VERSION "0.1"

NS_ :

BS_:

BU_: User ADB_PC_DC01

BO_ 8519744 DC01_Mode_Set: 2 User
 SG_ connection : 8|8@1+ (1,0) [0|0] ""  ADB_PC_DC01
 SG_ mode : 0|8@1+ (1,0) [0|0] ""  ADB_PC_DC01

BO_ 8519745 DC01_Mode_Applied: 2 ADB_PC_DC01
 SG_ connection : 8|8@1+ (1,0) [0|0] ""  User
 SG_ mode : 0|8@1+ (1,0) [0|0] ""  User

BO_ 8519746 DC01_faults: 8 ADB_PC_DC01

BO_ 8519747 DC01_warning: 8 ADB_PC_DC01

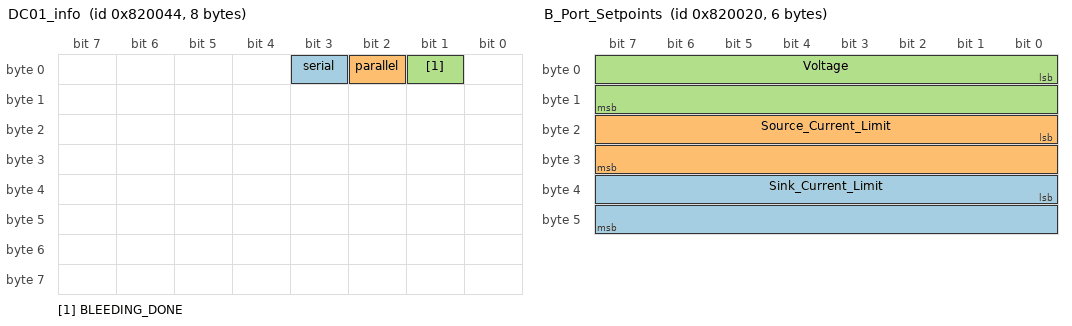
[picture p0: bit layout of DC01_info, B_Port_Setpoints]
BO_ 8519748 DC01_info: 8 ADB_PC_DC01
 SG_ serial : 3|1@1+ (1,0) [0|0] ""  User
 SG_ parallel : 2|1@1+ (1,0) [0|0] ""  User
 SG_ BLEEDING_DONE : 1|1@1+ (1,0) [0|0] ""  User

BO_ 8519712 B_Port_Setpoints: 6 User
 SG_ Sink_Current_Limit : 32|16@1+ (0.1,0) [0|220] "A"  ADB_PC_DC01
 SG_ Source_Current_Limit : 16|16@1+ (0.1,0) [0|220] "A"  ADB_PC_DC01
 SG_ Voltage : 0|16@1+ (0.1,0) [0|1500] "V"  ADB_PC_DC01

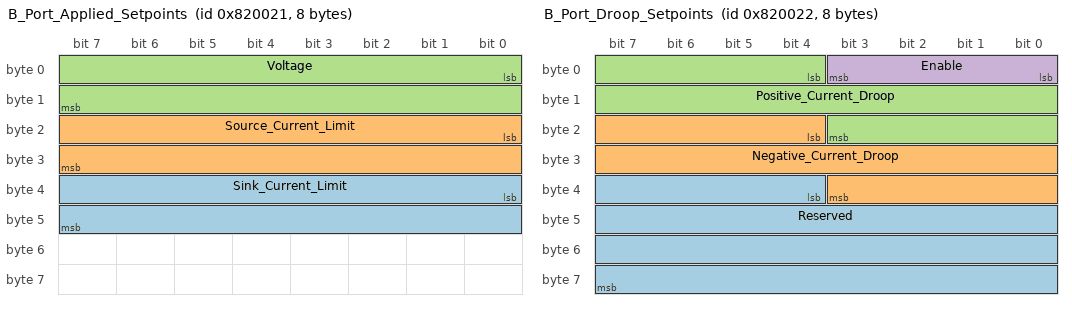
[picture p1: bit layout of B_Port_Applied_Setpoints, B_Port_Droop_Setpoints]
BO_ 8519713 B_Port_Applied_Setpoints: 8 ADB_PC_DC01
 SG_ Sink_Current_Limit : 32|16@1+ (0.1,0) [0|0] "A"  User
 SG_ Source_Current_Limit : 16|16@1+ (0.1,0) [0|0] "A"  User
 SG_ Voltage : 0|16@1+ (0.1,0) [0|0] "V"  User

BO_ 8519714 B_Port_Droop_Setpoints: 8 User
 SG_ Reserved : 36|28@1+ (1,0) [0|0] ""  ADB_PC_DC01
 SG_ Negative_Current_Droop : 20|16@1+ (0.01,0) [0|0] "Ohm"  ADB_PC_DC01
 SG_ Positive_Current_Droop : 4|16@1+ (0.01,0) [0|0] "Ohm"  ADB_PC_DC01
 SG_ Enable : 0|4@1+ (1,0) [0|0] ""  ADB_PC_DC01

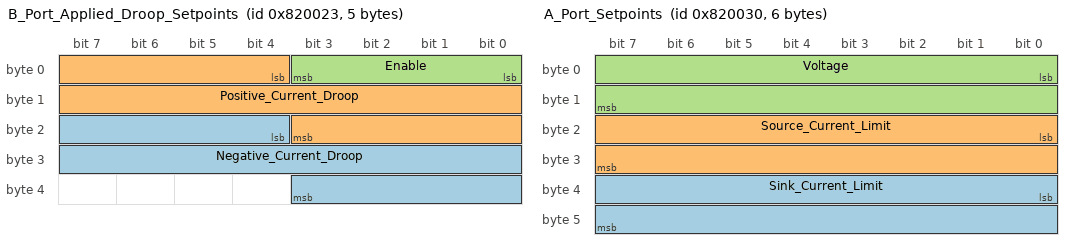
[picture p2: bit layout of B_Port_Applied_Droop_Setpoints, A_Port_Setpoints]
BO_ 8519715 B_Port_Applied_Droop_Setpoints: 5 ADB_PC_DC01
 SG_ Negative_Current_Droop : 20|16@1+ (0.01,0) [0|0] "Ohm"  User
 SG_ Positive_Current_Droop : 4|16@1+ (0.01,0) [0|0] "Ohm"  User
 SG_ Enable : 0|4@1+ (1,0) [0|0] ""  User

BO_ 8519716 B_Port_Measurements: 4 ADB_PC_DC01
 SG_ Current : 16|16@1- (0.1,0) [0|0] "A"  User
 SG_ Voltage : 0|16@1+ (0.1,0) [0|0] "V"  User

BO_ 8519730 A_Port_Measurements: 4 ADB_PC_DC01
 SG_ Current : 16|16@1- (0.1,0) [0|0] "A"  User
 SG_ Voltage : 0|16@1+ (0.1,0) [0|0] "V"  User

BO_ 8519728 A_Port_Setpoints: 6 User
 SG_ Sink_Current_Limit : 32|16@1+ (0.1,0) [0|220] "A"  ADB_PC_DC01
 SG_ Source_Current_Limit : 16|16@1+ (0.1,0) [0|220] "A"  ADB_PC_DC01
 SG_ Voltage : 0|16@1+ (0.1,0) [0|1500] "V"  ADB_PC_DC01

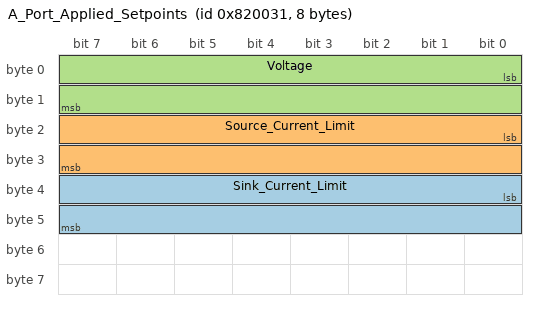
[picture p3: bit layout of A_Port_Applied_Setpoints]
BO_ 8519729 A_Port_Applied_Setpoints: 8 ADB_PC_DC01
 SG_ Sink_Current_Limit : 32|16@1+ (0.1,0) [0|0] "A"  User
 SG_ Source_Current_Limit : 16|16@1+ (0.1,0) [0|0] "A"  User
 SG_ Voltage : 0|16@1+ (0.1,0) [0|0] "V"  User

CM_ BO_ 8519744 "Set the mode of AC01";
CM_ SG_ 8519744 connection "require connection";
CM_ SG_ 8519744 mode "require mode";
CM_ BO_ 8519745 "read back the modes";
CM_ SG_ 8519745 connection "connection mode";
CM_ SG_ 8519745 mode "actual mode";
CM_ BO_ 8519746 "DC01 Critical and Error Faults";
CM_ BO_ 8519747 "DC01 Warning";
CM_ BO_ 8519748 "DC01 Info";
CM_ SG_ 8519748 serial "Afe are in series ";
CM_ SG_ 8519748 parallel "Afe are in parallel";
CM_ SG_ 8519748 BLEEDING_DONE "Current limited by power max ";
CM_ BO_ 8519712 "The setpoints control the behaviour of the B Port of the DC01";
CM_ SG_ 8519712 Sink_Current_Limit "The maximum current that the AC01 will sink into the B port";
CM_ SG_ 8519712 Source_Current_Limit "The maximum current that the DC01 will source on the B port";
CM_ SG_ 8519712 Voltage "Control the target B port voltage. This voltage will be maintained as long as the current required to do so is smaller than the current limits specified in this message";
CM_ BO_ 8519713 "The setpoints that are currently used by the DC01. This message allows to validate that the setpoints have been properly applied.";
CM_ SG_ 8519713 Sink_Current_Limit "The maximum amount of current that the DC01 will sink into the B port";
CM_ SG_ 8519713 Source_Current_Limit "The maximum current that the DC01 will source on the B Port";
CM_ SG_ 8519713 Voltage "The voltage target of the B port";
CM_ BO_ 8519714 "Setpoints for applying Droop on the B Port. Droop is needed for paralleling multiple DC01";
CM_ SG_ 8519714 Reserved "This space is reserved. This region should contain only '0's";
CM_ SG_ 8519714 Negative_Current_Droop "The droop resistance to apply for current flowing in to the B Port (DC current is negative)";
CM_ SG_ 8519714 Positive_Current_Droop "The droop resistance to apply for current flowing out of the B port (DC current is positive)";
CM_ SG_ 8519714 Enable "Enable DC Droop. If this feature is enabled the output voltage of the B port varies with output current.";
CM_ BO_ 8519715 "Droop setpoints that are applied by the DC01";
CM_ SG_ 8519715 Negative_Current_Droop "The droop resistance applied for current flowing in to the B Port (DC current is negative)";
CM_ SG_ 8519715 Positive_Current_Droop "The droop resistance applied for current flowing out of the B port (DC current is positive)";
CM_ SG_ 8519715 Enable "Show is DC Droop is enabled.";
CM_ BO_ 8519716 "Measurements of the B port";
CM_ SG_ 8519716 Current "Current through the B Port";
CM_ SG_ 8519716 Voltage "Voltage on the B Port";
CM_ BO_ 8519730 "Measurements of the A port";
CM_ SG_ 8519730 Current "Current through the A Port";
CM_ SG_ 8519730 Voltage "Voltage on the A Port";
CM_ BO_ 8519728 "The setpoints control the behaviour of the A Port of the DC01";
CM_ SG_ 8519728 Sink_Current_Limit "The maximum current that the AC01 will sink into the A port";
CM_ SG_ 8519728 Source_Current_Limit "The maximum current that the DC01 will source on the A port";
CM_ SG_ 8519728 Voltage "Control the target A port voltage. This voltage will be maintained as long as the current required to do so is smaller than the current limits specified in this message";
CM_ BO_ 8519729 "The setpoints that are currently used by the DC01. This message allows to validate that the setpoints have been properly applied.";
CM_ SG_ 8519729 Sink_Current_Limit "The maximum amount of current that the DC01 will sink into the A port";
CM_ SG_ 8519729 Source_Current_Limit "The maximum current that the DC01 will source on the A Port";
CM_ SG_ 8519729 Voltage "The voltage target of the A port";
BA_DEF_ BO_  "GenMsgCycleTime" INT 0 65535;
BA_DEF_DEF_  "GenMsgCycleTime" 0;
BA_ "GenMsgCycleTime" BO_ 8519745 1000;
BA_ "GenMsgCycleTime" BO_ 8519746 1000;
BA_ "GenMsgCycleTime" BO_ 8519747 1000;
BA_ "GenMsgCycleTime" BO_ 8519748 1000;
BA_ "GenMsgCycleTime" BO_ 8519712 1000;
BA_ "GenMsgCycleTime" BO_ 8519713 1000;
BA_ "GenMsgCycleTime" BO_ 8519715 1000;
BA_ "GenMsgCycleTime" BO_ 8519716 100;
BA_ "GenMsgCycleTime" BO_ 8519730 100;
BA_ "GenMsgCycleTime" BO_ 8519728 1000;
BA_ "GenMsgCycleTime" BO_ 8519729 1000;
VAL_ 8519744 connection 0 "automatic" 1 "forced_serial" 2 "forced_parallel" ;
VAL_ 8519744 mode 0 "B_port_Controlled" 1 "A_port_Controlled" 2 "Bleeding" ;
VAL_ 8519745 connection 0 "open" 1 "serial" 2 "parallel" ;
VAL_ 8519745 mode 0 "B_side_Controlled" 1 "A_side_Controlled" 2 "Bleeding" ;
VAL_ 8519748 serial 0 "Clear" 1 "Info" ;
VAL_ 8519748 parallel 0 "Clear" 1 "Info" ;
VAL_ 8519748 BLEEDING_DONE 0 "Clear" 1 "Info" ;
VAL_ 8519714 Enable 1 "Enabled" 0 "Disabled" ;
VAL_ 8519715 Enable 1 "Enabled" 0 "Disabled" ;
